# ioat91sam7s256 register map
Registers are 32-bit, access not given, no defined reset value unless marked. A register's access mark holds for its fields unless they carry their own. Addresses are absolute; registers are grouped by the start of their names; [hi:lo] are bit positions; {n}, {i} and the like mark numbered series; 'fields as' and 'values as' point back to an identical list.

## US1
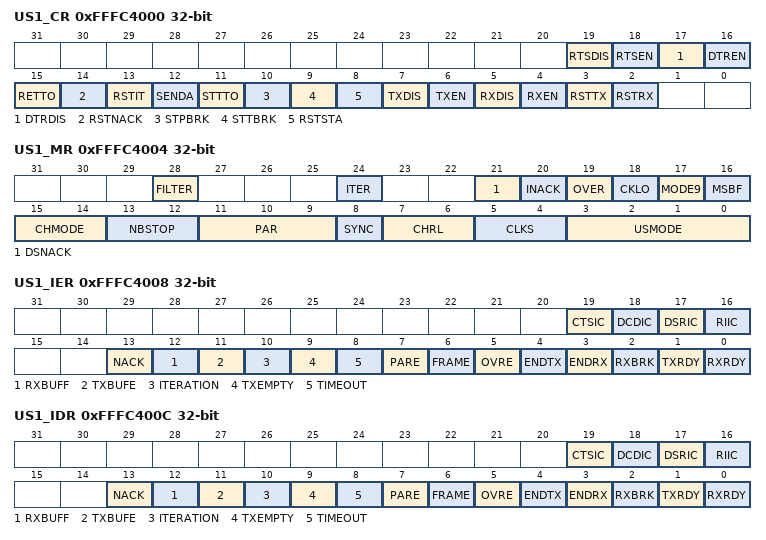
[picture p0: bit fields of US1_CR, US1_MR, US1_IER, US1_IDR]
0xFFFC4000 US1_CR
  [19] RTSDIS, [18] RTSEN, [17] DTRDIS, [16] DTREN, [15] RETTO, [14] RSTNACK, [13] RSTIT, [12] SENDA, [11] STTTO, [10] STPBRK, [9] STTBRK, [8] RSTSTA, [7] TXDIS, [6] TXEN, [5] RXDIS, [4] RXEN, [3] RSTTX, [2] RSTRX
0xFFFC4004 US1_MR
  [28] FILTER, [24] ITER, [21] DSNACK, [20] INACK, [19] OVER, [18] CKLO, [17] MODE9, [16] MSBF, [15:14] CHMODE, [13:12] NBSTOP, [11:9] PAR, [8] SYNC, [7:6] CHRL, [5:4] CLKS, [3:0] USMODE
0xFFFC4008 US1_IER
  [19] CTSIC, [18] DCDIC, [17] DSRIC, [16] RIIC, [13] NACK, [12] RXBUFF, [11] TXBUFE, [10] ITERATION, [9] TXEMPTY, [8] TIMEOUT, [7] PARE, [6] FRAME, [5] OVRE, [4] ENDTX, [3] ENDRX, [2] RXBRK, [1] TXRDY, [0] RXRDY
0xFFFC400C US1_IDR
  fields as US1_IER
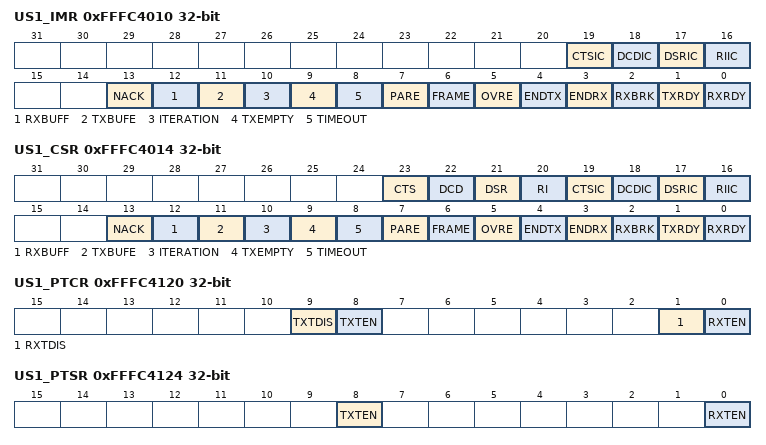
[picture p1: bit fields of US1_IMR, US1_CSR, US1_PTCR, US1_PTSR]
0xFFFC4010 US1_IMR
  fields as US1_IER
0xFFFC4014 US1_CSR
  [23] CTS, [22] DCD, [21] DSR, [20] RI, [19] CTSIC, [18] DCDIC, [17] DSRIC, [16] RIIC, [13] NACK, [12] RXBUFF, [11] TXBUFE, [10] ITERATION, [9] TXEMPTY, [8] TIMEOUT, [7] PARE, [6] FRAME, [5] OVRE, [4] ENDTX, [3] ENDRX, [2] RXBRK, [1] TXRDY, [0] RXRDY
0xFFFC4018 US1_RHR
0xFFFC401C US1_THR
0xFFFC4020 US1_BRGR
0xFFFC4024 US1_RTOR
0xFFFC4028 US1_TTGR
0xFFFC4040 US1_FIDI
0xFFFC4044 US1_NER
0xFFFC404C US1_IF
0xFFFC4100 US1_RPR
0xFFFC4104 US1_RCR
0xFFFC4108 US1_TPR
0xFFFC410C US1_TCR
0xFFFC4110 US1_RNPR
0xFFFC4114 US1_RNCR
0xFFFC4118 US1_TNPR
0xFFFC411C US1_TNCR
0xFFFC4120 US1_PTCR
  [9] TXTDIS, [8] TXTEN, [1] RXTDIS, [0] RXTEN
0xFFFC4124 US1_PTSR
  [8] TXTEN, [0] RXTEN

## US0
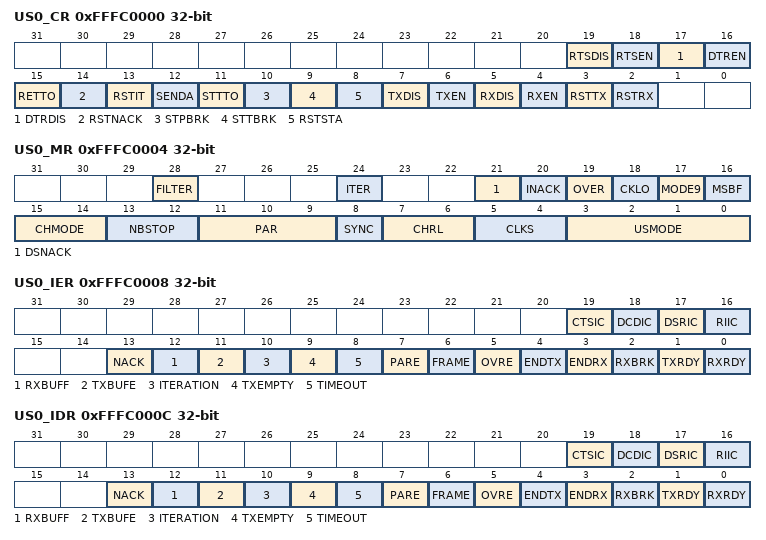
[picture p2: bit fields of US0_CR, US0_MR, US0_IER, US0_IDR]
0xFFFC0000 US0_CR
  [19] RTSDIS, [18] RTSEN, [17] DTRDIS, [16] DTREN, [15] RETTO, [14] RSTNACK, [13] RSTIT, [12] SENDA, [11] STTTO, [10] STPBRK, [9] STTBRK, [8] RSTSTA, [7] TXDIS, [6] TXEN, [5] RXDIS, [4] RXEN, [3] RSTTX, [2] RSTRX
0xFFFC0004 US0_MR
  [28] FILTER, [24] ITER, [21] DSNACK, [20] INACK, [19] OVER, [18] CKLO, [17] MODE9, [16] MSBF, [15:14] CHMODE, [13:12] NBSTOP, [11:9] PAR, [8] SYNC, [7:6] CHRL, [5:4] CLKS, [3:0] USMODE
0xFFFC0008 US0_IER
  [19] CTSIC, [18] DCDIC, [17] DSRIC, [16] RIIC, [13] NACK, [12] RXBUFF, [11] TXBUFE, [10] ITERATION, [9] TXEMPTY, [8] TIMEOUT, [7] PARE, [6] FRAME, [5] OVRE, [4] ENDTX, [3] ENDRX, [2] RXBRK, [1] TXRDY, [0] RXRDY
0xFFFC000C US0_IDR
  fields as US0_IER
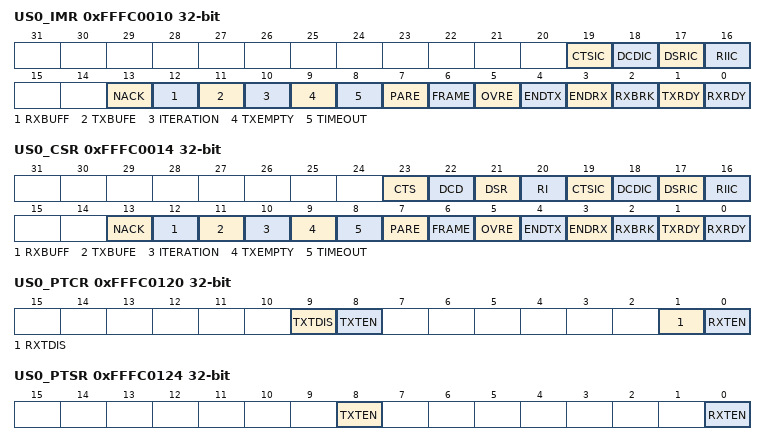
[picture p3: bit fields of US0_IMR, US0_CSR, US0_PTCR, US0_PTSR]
0xFFFC0010 US0_IMR
  fields as US0_IER
0xFFFC0014 US0_CSR
  [23] CTS, [22] DCD, [21] DSR, [20] RI, [19] CTSIC, [18] DCDIC, [17] DSRIC, [16] RIIC, [13] NACK, [12] RXBUFF, [11] TXBUFE, [10] ITERATION, [9] TXEMPTY, [8] TIMEOUT, [7] PARE, [6] FRAME, [5] OVRE, [4] ENDTX, [3] ENDRX, [2] RXBRK, [1] TXRDY, [0] RXRDY
0xFFFC0018 US0_RHR
0xFFFC001C US0_THR
0xFFFC0020 US0_BRGR
0xFFFC0024 US0_RTOR
0xFFFC0028 US0_TTGR
0xFFFC0040 US0_FIDI
0xFFFC0044 US0_NER
0xFFFC004C US0_IF
0xFFFC0100 US0_RPR
0xFFFC0104 US0_RCR
0xFFFC0108 US0_TPR
0xFFFC010C US0_TCR
0xFFFC0110 US0_RNPR
0xFFFC0114 US0_RNCR
0xFFFC0118 US0_TNPR
0xFFFC011C US0_TNCR
0xFFFC0120 US0_PTCR
  [9] TXTDIS, [8] TXTEN, [1] RXTDIS, [0] RXTEN
0xFFFC0124 US0_PTSR
  [8] TXTEN, [0] RXTEN

## TWI
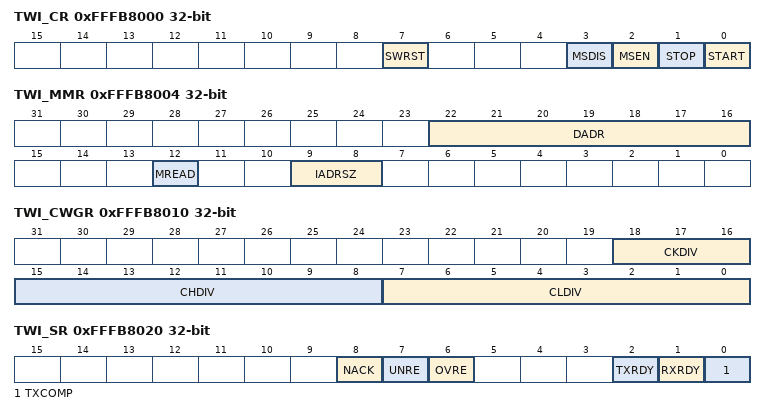
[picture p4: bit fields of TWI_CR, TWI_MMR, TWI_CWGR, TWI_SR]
0xFFFB8000 TWI_CR
  [7] SWRST, [3] MSDIS, [2] MSEN, [1] STOP, [0] START
0xFFFB8004 TWI_MMR
  [22:16] DADR, [12] MREAD, [9:8] IADRSZ
0xFFFB800C TWI_IADR
0xFFFB8010 TWI_CWGR
  [18:16] CKDIV, [15:8] CHDIV, [7:0] CLDIV
0xFFFB8020 TWI_SR
  [8] NACK, [7] UNRE, [6] OVRE, [2] TXRDY, [1] RXRDY, [0] TXCOMP
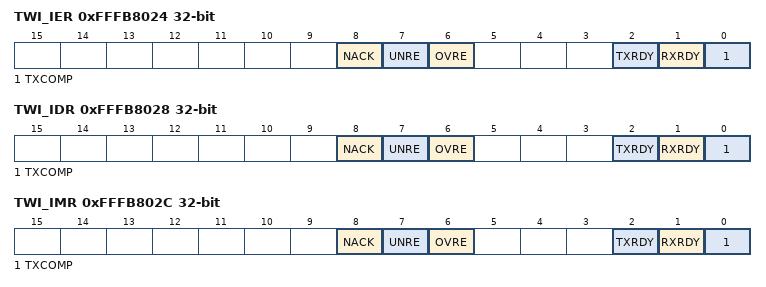
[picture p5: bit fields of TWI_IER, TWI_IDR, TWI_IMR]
0xFFFB8024 TWI_IER
  [8] NACK, [7] UNRE, [6] OVRE, [2] TXRDY, [1] RXRDY, [0] TXCOMP
0xFFFB8028 TWI_IDR
  [8] NACK, [7] UNRE, [6] OVRE, [2] TXRDY, [1] RXRDY, [0] TXCOMP
0xFFFB802C TWI_IMR
  [8] NACK, [7] UNRE, [6] OVRE, [2] TXRDY, [1] RXRDY, [0] TXCOMP
0xFFFB8030 TWI_RHR
0xFFFB8034 TWI_THR

## TC0
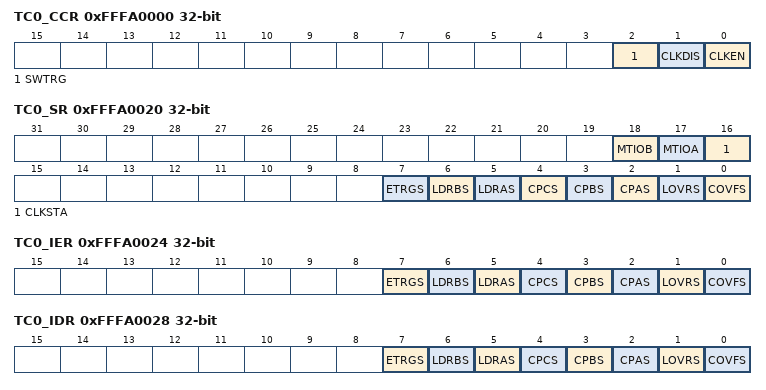
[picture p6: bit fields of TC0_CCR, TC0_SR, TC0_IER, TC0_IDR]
0xFFFA0000 TC0_CCR
  [2] SWTRG, [1] CLKDIS, [0] CLKEN
0xFFFA0004 TC0_CMR
  [31:30] BSWTRG, [29:28] BEEVT, [27:26] BCPC, [25:24] BCPB, [23:22] ASWTRG, [21:20] AEEVT, [19:18] ACPC, [19:18] LDRB, [17:16] ACPA, [17:16] LDRA, [15] WAVE, [14] CPCTRG, [14:13] WAVESEL, [12] ENETRG, [11:10] EEVT, [10] ABETRG, [9:8] ETRGEDG, [9:8] EEVTEDG, [7] CPCDIS, [7] LDBDIS, [6] CPCSTOP, [6] LDBSTOP, [5:4] BURST, [3] CLKI, [2:0] CLKS
0xFFFA0010 TC0_CV
0xFFFA0014 TC0_RA
0xFFFA0018 TC0_RB
0xFFFA001C TC0_RC
0xFFFA0020 TC0_SR
  [18] MTIOB, [17] MTIOA, [16] CLKSTA, [7] ETRGS, [6] LDRBS, [5] LDRAS, [4] CPCS, [3] CPBS, [2] CPAS, [1] LOVRS, [0] COVFS
0xFFFA0024 TC0_IER
  [7] ETRGS, [6] LDRBS, [5] LDRAS, [4] CPCS, [3] CPBS, [2] CPAS, [1] LOVRS, [0] COVFS
0xFFFA0028 TC0_IDR
  fields as TC0_IER
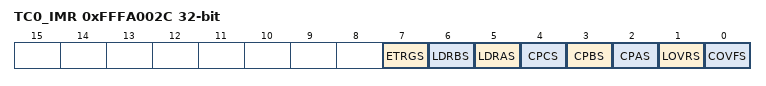
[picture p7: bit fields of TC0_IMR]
0xFFFA002C TC0_IMR
  fields as TC0_IER

## TC1
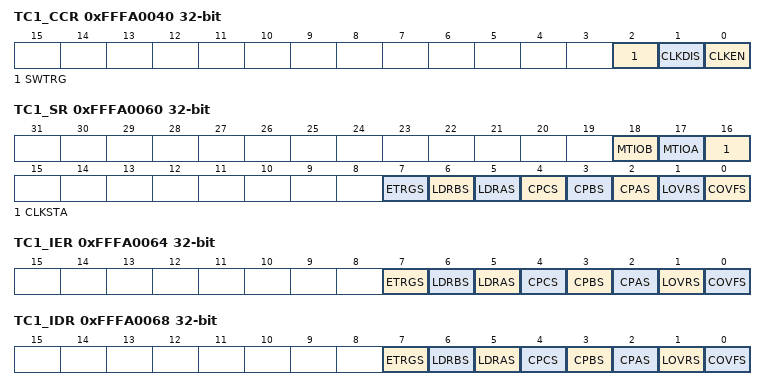
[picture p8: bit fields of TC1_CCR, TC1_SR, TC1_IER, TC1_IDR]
0xFFFA0040 TC1_CCR
  [2] SWTRG, [1] CLKDIS, [0] CLKEN
0xFFFA0044 TC1_CMR
  [31:30] BSWTRG, [29:28] BEEVT, [27:26] BCPC, [25:24] BCPB, [23:22] ASWTRG, [21:20] AEEVT, [19:18] ACPC, [19:18] LDRB, [17:16] ACPA, [17:16] LDRA, [15] WAVE, [14] CPCTRG, [14:13] WAVESEL, [12] ENETRG, [11:10] EEVT, [10] ABETRG, [9:8] ETRGEDG, [9:8] EEVTEDG, [7] CPCDIS, [7] LDBDIS, [6] CPCSTOP, [6] LDBSTOP, [5:4] BURST, [3] CLKI, [2:0] CLKS
0xFFFA0050 TC1_CV
0xFFFA0054 TC1_RA
0xFFFA0058 TC1_RB
0xFFFA005C TC1_RC
0xFFFA0060 TC1_SR
  [18] MTIOB, [17] MTIOA, [16] CLKSTA, [7] ETRGS, [6] LDRBS, [5] LDRAS, [4] CPCS, [3] CPBS, [2] CPAS, [1] LOVRS, [0] COVFS
0xFFFA0064 TC1_IER
  [7] ETRGS, [6] LDRBS, [5] LDRAS, [4] CPCS, [3] CPBS, [2] CPAS, [1] LOVRS, [0] COVFS
0xFFFA0068 TC1_IDR
  fields as TC1_IER
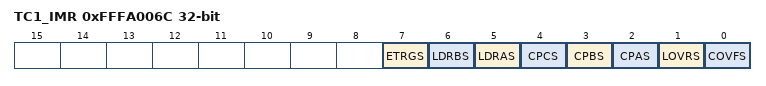
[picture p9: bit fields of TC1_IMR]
0xFFFA006C TC1_IMR
  fields as TC1_IER

## TC2
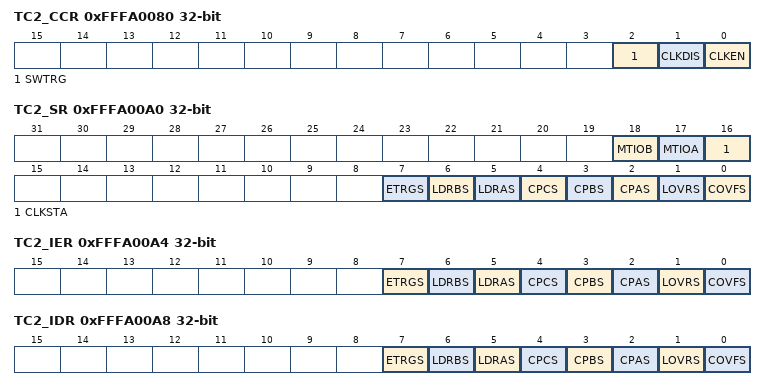
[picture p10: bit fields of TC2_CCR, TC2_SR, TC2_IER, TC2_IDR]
0xFFFA0080 TC2_CCR
  [2] SWTRG, [1] CLKDIS, [0] CLKEN
0xFFFA0084 TC2_CMR
  [31:30] BSWTRG, [29:28] BEEVT, [27:26] BCPC, [25:24] BCPB, [23:22] ASWTRG, [21:20] AEEVT, [19:18] ACPC, [19:18] LDRB, [17:16] ACPA, [17:16] LDRA, [15] WAVE, [14] CPCTRG, [14:13] WAVESEL, [12] ENETRG, [11:10] EEVT, [10] ABETRG, [9:8] ETRGEDG, [9:8] EEVTEDG, [7] CPCDIS, [7] LDBDIS, [6] CPCSTOP, [6] LDBSTOP, [5:4] BURST, [3] CLKI, [2:0] CLKS
0xFFFA0090 TC2_CV
0xFFFA0094 TC2_RA
0xFFFA0098 TC2_RB
0xFFFA009C TC2_RC
0xFFFA00A0 TC2_SR
  [18] MTIOB, [17] MTIOA, [16] CLKSTA, [7] ETRGS, [6] LDRBS, [5] LDRAS, [4] CPCS, [3] CPBS, [2] CPAS, [1] LOVRS, [0] COVFS
0xFFFA00A4 TC2_IER
  [7] ETRGS, [6] LDRBS, [5] LDRAS, [4] CPCS, [3] CPBS, [2] CPAS, [1] LOVRS, [0] COVFS
0xFFFA00A8 TC2_IDR
  fields as TC2_IER
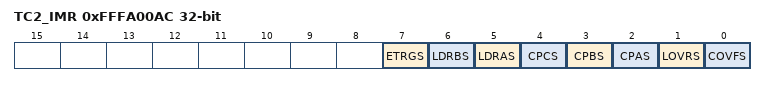
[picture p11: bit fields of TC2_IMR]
0xFFFA00AC TC2_IMR
  fields as TC2_IER

## TCB
0xFFFA00C0 TCB_BCR
  [0] SYNC
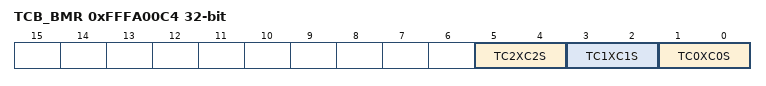
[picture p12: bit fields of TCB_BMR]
0xFFFA00C4 TCB_BMR
  [5:4] TC2XC2S, [3:2] TC1XC1S, [1:0] TC0XC0S

## PWMC
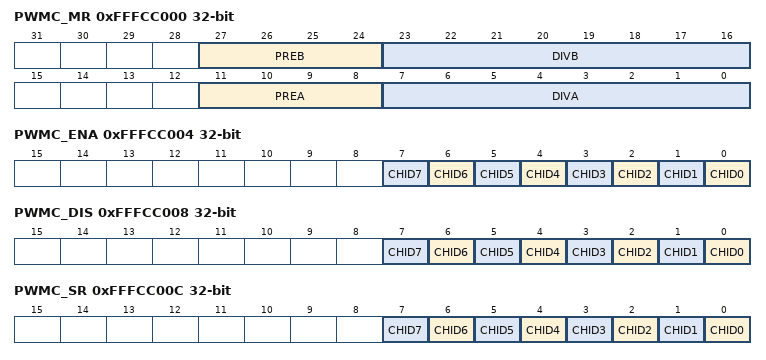
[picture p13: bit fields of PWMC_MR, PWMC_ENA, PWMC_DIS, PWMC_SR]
0xFFFCC000 PWMC_MR
  [27:24] PREB, [23:16] DIVB, [11:8] PREA, [7:0] DIVA
0xFFFCC004 PWMC_ENA
  [n] CHID{n} (n=0..7)
0xFFFCC008 PWMC_DIS
  [n] CHID{n} (n=0..7)
0xFFFCC00C PWMC_SR
  [n] CHID{n} (n=0..7)
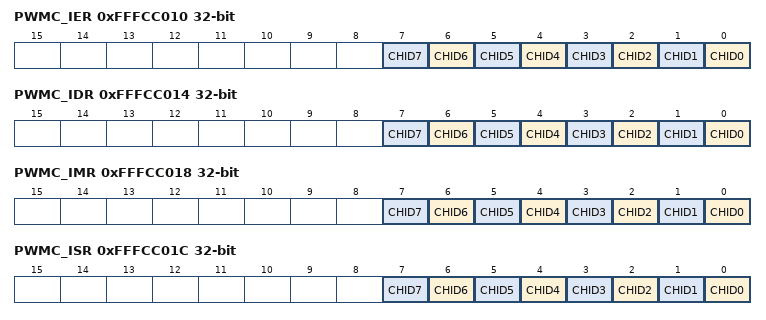
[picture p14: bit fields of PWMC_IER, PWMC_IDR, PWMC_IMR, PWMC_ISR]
0xFFFCC010 PWMC_IER
  [n] CHID{n} (n=0..7)
0xFFFCC014 PWMC_IDR
  [n] CHID{n} (n=0..7)
0xFFFCC018 PWMC_IMR
  [n] CHID{n} (n=0..7)
0xFFFCC01C PWMC_ISR
  [n] CHID{n} (n=0..7)
0xFFFCC0FC PWMC_VR
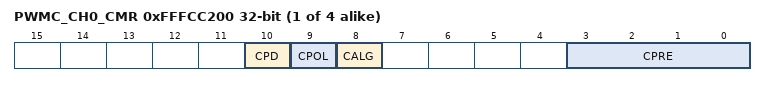
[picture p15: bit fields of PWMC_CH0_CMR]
{0xFFFCC200+0x20*i} PWMC_CH{i}_CMR (i=0..3)
  [10] CPD, [9] CPOL, [8] CALG, [3:0] CPRE
{0xFFFCC204+0x20*i} PWMC_CH{i}_CDTYR (i=0..3)
  [31:0] CDTY
{0xFFFCC208+0x20*i} PWMC_CH{i}_CPRDR (i=0..3)
  [31:0] CPRD
{0xFFFCC20C+0x20*i} PWMC_CH{i}_CCNTR (i=0..3)
  [31:0] CCNT
{0xFFFCC210+0x20*i} PWMC_CH{i}_CUPDR (i=0..3)
  [31:0] CUPD
{0xFFFCC214+0x20*i} PWMC_CH{i}_Reserved (i=0..3)

## UDP
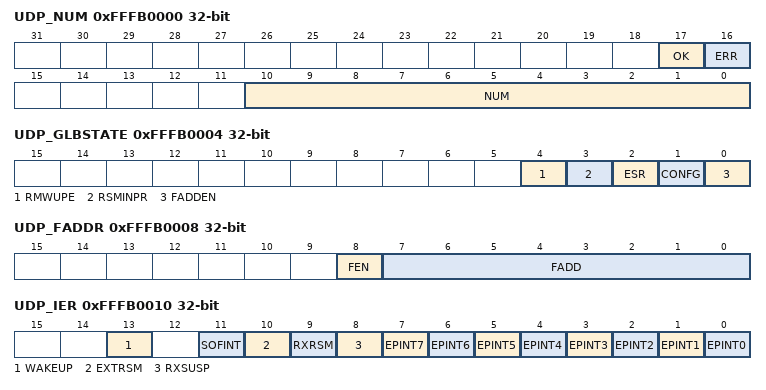
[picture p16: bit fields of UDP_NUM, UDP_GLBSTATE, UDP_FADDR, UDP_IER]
0xFFFB0000 UDP_NUM
  [17] OK, [16] ERR, [10:0] NUM
0xFFFB0004 UDP_GLBSTATE
  [4] RMWUPE, [3] RSMINPR, [2] ESR, [1] CONFG, [0] FADDEN
0xFFFB0008 UDP_FADDR
  [8] FEN, [7:0] FADD
0xFFFB0010 UDP_IER
  [13] WAKEUP, [11] SOFINT, [10] EXTRSM, [9] RXRSM, [8] RXSUSP, [n] EPINT{n} (n=0..7)
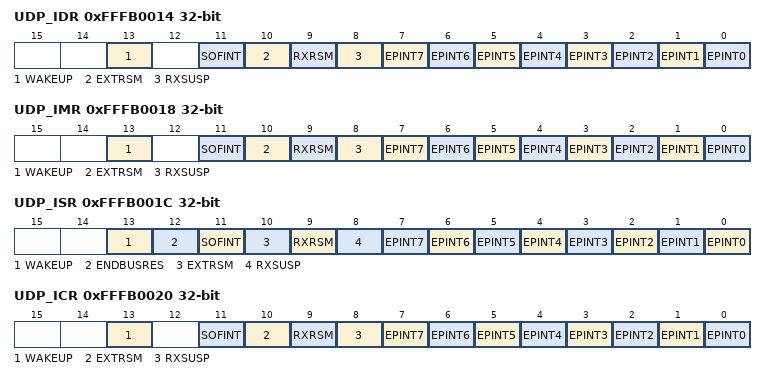
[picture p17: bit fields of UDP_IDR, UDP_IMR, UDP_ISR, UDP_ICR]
0xFFFB0014 UDP_IDR
  fields as UDP_IER
0xFFFB0018 UDP_IMR
  fields as UDP_IER
0xFFFB001C UDP_ISR
  [13] WAKEUP, [12] ENDBUSRES, [11] SOFINT, [10] EXTRSM, [9] RXRSM, [8] RXSUSP, [n] EPINT{n} (n=0..7)
0xFFFB0020 UDP_ICR
  fields as UDP_IER
0xFFFB0028 UDP_RSTEP
  [n] EP{n} (n=0..7)
0xFFFB0030 UDP_CSR
  [26:16] RXBYTECNT, [15] EPEDS, [11] DTGLE, [10:8] EPTYPE, [7] DIR, [6] BK1, [5] FORCESTALL, [4] TXPKTRDY, [3] ISOERROR, [2] RXSETUP, [1] BK0, [0] TXCOMP
0xFFFB0050 UDP_FDR
0xFFFB0074 UDP_TXVC
  [9] PUON, [8] TXVDIS

## SFR
0xFFFFFD60 VREG_MR
  [0] PSTDBY
